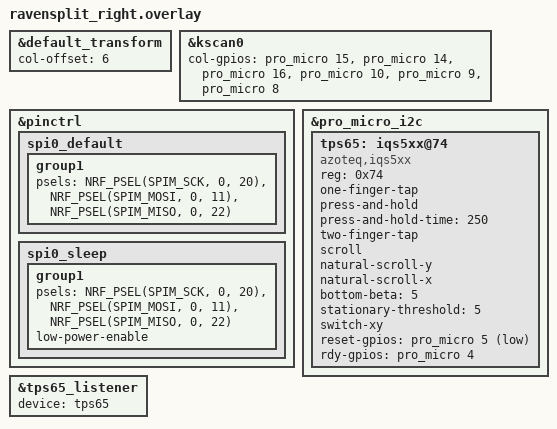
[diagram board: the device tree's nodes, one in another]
#include "ravensplit.dtsi"

&default_transform {
    col-offset = <6>;
};

&kscan0 {
    col-gpios
        = <&pro_micro 15 GPIO_ACTIVE_HIGH> // C5
        , <&pro_micro 14 GPIO_ACTIVE_HIGH> // C4
        , <&pro_micro 16 GPIO_ACTIVE_HIGH> // C3
        , <&pro_micro 10 GPIO_ACTIVE_HIGH> // C2
        , <&pro_micro 9 GPIO_ACTIVE_HIGH>  // C2
        , <&pro_micro 8 GPIO_ACTIVE_HIGH>  // C1
        ;
};

&pinctrl {
    /* configuration for spi0 device, default state */
    spi0_default: spi0_default {
        /* node name is arbitrary */
        group1 {
            /* main role: configure P0.20 (D3) as SPI clock, P0.11 (D7) as SPI MOSI, P0.22 (D4) as SPI MISO */
            psels = <NRF_PSEL(SPIM_SCK, 0, 20)>,
                    <NRF_PSEL(SPIM_MOSI, 0, 11)>,
                    <NRF_PSEL(SPIM_MISO, 0, 22)>;
        };
    };
    /* configuration for spi0 device, sleep state */
    spi0_sleep: spi0_sleep {
        group1 {
            /* main role: configure P0.20 (D3) as SPI clock, P0.11 (D7) as SPI MOSI, P0.22 (D4) as SPI MISO */
            psels = <NRF_PSEL(SPIM_SCK, 0, 20)>,
                    <NRF_PSEL(SPIM_MOSI, 0, 11)>,
                    <NRF_PSEL(SPIM_MISO, 0, 22)>;
            low-power-enable;
        };
    };
};

&pro_micro_i2c {
    status = "okay";

    tps65: iqs5xx@74 {
        status = "okay";
        compatible = "azoteq,iqs5xx";
        reg = <0x74>;

        one-finger-tap;
        press-and-hold;
        press-and-hold-time = <250>;
        two-finger-tap;

        scroll;
        natural-scroll-y;
        natural-scroll-x;

        bottom-beta = <5>;
        stationary-threshold = <5>;

        switch-xy;

        reset-gpios = <&pro_micro 5 GPIO_ACTIVE_LOW>; /* 024 */
        rdy-gpios = <&pro_micro 4 GPIO_ACTIVE_HIGH>; /* 022 */
    };
};

&tps65_listener {
    status = "okay";
    device = <&tps65>;
};
